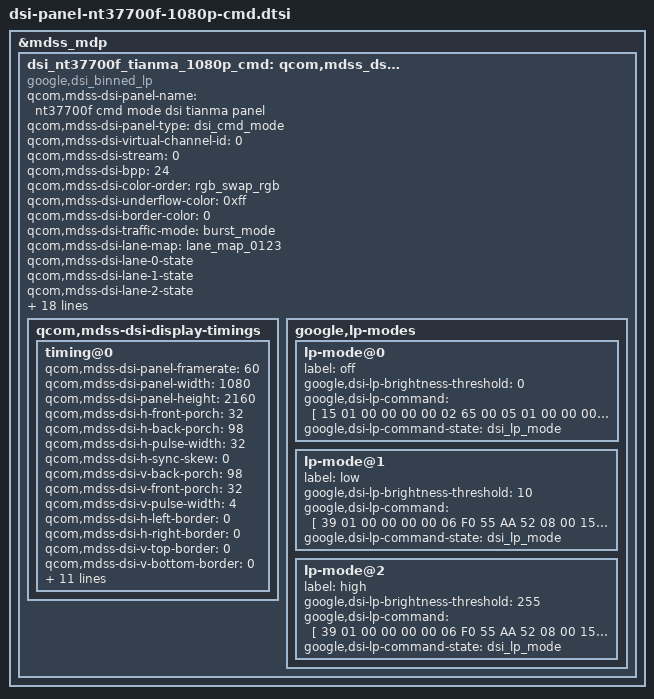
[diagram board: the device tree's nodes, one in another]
/* Copyright (c) 2018, The Linux Foundation. All rights reserved.
 *
 * This program is free software; you can redistribute it and/or modify
 * it under the terms of the GNU General Public License version 2 and
 * only version 2 as published by the Free Software Foundation.
 *
 * This program is distributed in the hope that it will be useful,
 * but WITHOUT ANY WARRANTY; without even the implied warranty of
 * MERCHANTABILITY or FITNESS FOR A PARTICULAR PURPOSE.  See the
 * GNU General Public License for more details.
 */

&mdss_mdp {
	dsi_nt37700f_tianma_1080p_cmd: qcom,mdss_dsi_nt37700f_tianma_1080p_cmd {
		compatible = "google,dsi_binned_lp";

		qcom,mdss-dsi-panel-name = "nt37700f cmd mode dsi tianma panel";
		qcom,mdss-dsi-panel-type = "dsi_cmd_mode";
		qcom,mdss-dsi-virtual-channel-id = <0>;
		qcom,mdss-dsi-stream = <0>;
		qcom,mdss-dsi-bpp = <24>;
		qcom,mdss-dsi-color-order = "rgb_swap_rgb";
		qcom,mdss-dsi-underflow-color = <0xff>;
		qcom,mdss-dsi-border-color = <0>;
		qcom,mdss-dsi-traffic-mode = "burst_mode";
		qcom,mdss-dsi-lane-map = "lane_map_0123";
		qcom,mdss-dsi-lane-0-state;
		qcom,mdss-dsi-lane-1-state;
		qcom,mdss-dsi-lane-2-state;
		qcom,mdss-dsi-lane-3-state;
		qcom,mdss-dsi-reset-sequence = <0 1>, <1 10>;
		qcom,mdss-dsi-dma-trigger = "trigger_sw";
		qcom,mdss-dsi-mdp-trigger = "none";
		qcom,mdss-dsi-te-pin-select = <1>;
		qcom,mdss-dsi-wr-mem-start = <0x2c>;
		qcom,mdss-dsi-wr-mem-continue = <0x3c>;
		qcom,mdss-dsi-te-dcs-command = <1>;
		qcom,mdss-dsi-te-check-enable;
		qcom,mdss-dsi-te-using-te-pin;
		qcom,mdss-dsi-lp11-init;
		qcom,mdss-dsi-tx-eot-append;

		qcom,mdss-pan-physical-width-dimension = <69>;
		qcom,mdss-pan-physical-height-dimension = <137>;

		qcom,mdss-dsi-bl-pmic-control-type = "bl_ctrl_dcs";
		qcom,mdss-dsi-bl-min-level = <9>;
		qcom,mdss-dsi-bl-max-level = <2047>; /* 11 bit */

		qcom,mdss-dsi-display-timings {
			timing@0 {
				qcom,mdss-dsi-panel-framerate = <60>;
				qcom,mdss-dsi-panel-width = <1080>;
				qcom,mdss-dsi-panel-height = <2160>;
				qcom,mdss-dsi-h-front-porch = <32>;
				qcom,mdss-dsi-h-back-porch = <98>;
				qcom,mdss-dsi-h-pulse-width = <32>;
				qcom,mdss-dsi-h-sync-skew = <0>;
				qcom,mdss-dsi-v-back-porch = <98>;
				qcom,mdss-dsi-v-front-porch = <32>;
				qcom,mdss-dsi-v-pulse-width = <4>;
				qcom,mdss-dsi-h-left-border = <0>;
				qcom,mdss-dsi-h-right-border = <0>;
				qcom,mdss-dsi-v-top-border = <0>;
				qcom,mdss-dsi-v-bottom-border = <0>;
				qcom,mdss-dsi-on-command = [
					39 01 00 00 00 00 06 F0 55 AA 52 08 00
					15 01 00 00 00 00 02 C0 56
					15 01 00 00 00 00 02 CA 52
					15 01 00 00 00 00 02 6F 06
					39 01 00 00 00 00 03 B5 2B 1A
					39 01 00 00 00 00 06 F0 55 AA 52 08 01
					39 01 00 00 00 00 03 CD 04 82
					39 01 00 00 00 00 06 F0 55 AA 52 08 02
					15 01 00 00 00 00 02 CC 00
					39 01 00 00 00 00 05 FF AA 55 A5 80
					15 01 00 00 00 00 02 6F 55
					15 01 00 00 00 00 02 F6 00
					15 01 00 00 00 00 02 6F 56
					15 01 00 00 00 00 02 F6 00
					39 01 00 00 00 00 05 FF AA 55 A5 81
					15 01 00 00 00 00 02 6F 07
					15 01 00 00 00 00 02 F3 07
					15 01 00 00 00 00 02 6F 05
					15 01 00 00 00 00 02 F3 25
					15 01 00 00 00 00 02 90 01
					39 01 00 00 00 00 05 2A 00 00 04 37
					39 01 00 00 00 00 05 2B 00 00 08 6F
					15 01 00 00 00 00 02 53 20
					15 01 00 00 00 00 02 35 00
					39 01 00 00 00 00 06 F0 55 AA 52 08 00
					15 01 00 00 00 00 02 C0 56
					39 01 00 00 00 00 06 F0 55 AA 52 08 02
					15 01 00 00 00 00 02 CD 00
					39 01 00 00 00 00 06 F0 55 AA 52 08 04
					39 01 00 00 00 00 03 D0 11 64
					15 01 00 00 00 00 02 6F 09
					15 01 00 00 00 00 04 B1 20 E6 08
					05 01 00 00 78 00 01 11
					05 01 00 00 00 00 01 29
				];
				qcom,mdss-dsi-off-command = [
					05 01 00 00 32 00 01 28
					05 01 00 00 64 00 01 10
				];
				qcom,mdss-dsi-lp1-command = [
					39 01 00 00 00 00 06 F0 55 AA 52 08 00
					15 01 00 00 00 00 02 6F 09
					15 01 00 00 00 00 02 B2 30
					/* emission 0x820: 50nit */
					39 01 00 00 00 00 1F B4
						83 33 33 33 33 33 33 33 33 38
						84 84 84 84 84 84 84 84 84 84
						84 84 84 84 84 84 84 84 84 20
					39 01 00 00 00 00 06 F0 55 AA 52 08 00
					15 01 00 00 00 00 02 6F 01
					39 01 00 00 00 00 04 C6 11 11 11
					15 01 00 00 00 00 02 6F 02
					15 01 00 00 00 00 02 C0 00
					39 01 00 00 00 00 06 F0 55 AA 52 08 01
					15 01 00 00 00 00 02 D2 10
					39 01 00 00 00 00 05 FF AA 55 A5 81
					15 01 00 00 00 00 02 6F 12
					15 01 00 00 00 00 02 F3 01
					05 01 00 00 00 00 01 39
					39 01 00 00 00 00 02 65 01
				];
				qcom,mdss-dsi-nolp-command = [
					15 01 00 00 00 00 02 65 00
					05 01 00 00 00 00 01 38
				];
				qcom,mdss-dsi-on-command-state = "dsi_lp_mode";
				qcom,mdss-dsi-off-command-state = "dsi_lp_mode";
				qcom,mdss-dsi-h-sync-pulse = <0>;
			};
		};

		google,lp-modes {
			lp-mode@0 {
				label = "off";
				google,dsi-lp-brightness-threshold = <0>;
				google,dsi-lp-command = [
					15 01 00 00 00 00 02 65 00
					05 01 00 00 00 00 01 38
				];
				google,dsi-lp-command-state = "dsi_lp_mode";
			};

			lp-mode@1 {
				label = "low";
				google,dsi-lp-brightness-threshold = <10>;
				google,dsi-lp-command = [
					39 01 00 00 00 00 06 F0 55 AA 52 08 00
					15 01 00 00 00 00 02 6F 09
					15 01 00 00 00 00 02 B2 30
					/* emission 0x871: 10nit */
					39 01 00 00 00 00 1F B4
						83 33 33 33 33 33 33 33 33 38
						84 84 84 84 84 84 84 84 84 84
						84 84 84 84 84 84 84 84 84 71
					39 01 00 00 00 00 06 F0 55 AA 52 08 00
					15 01 00 00 00 00 02 6F 01
					39 01 00 00 00 00 04 C6 11 11 11
					15 01 00 00 00 00 02 6F 02
					15 01 00 00 00 00 02 C0 00
					39 01 00 00 00 00 06 F0 55 AA 52 08 01
					15 01 00 00 00 00 02 D2 10
					39 01 00 00 00 00 05 FF AA 55 A5 81
					15 01 00 00 00 00 02 6F 12
					15 01 00 00 00 00 02 F3 01
					05 01 00 00 00 00 01 39
					39 01 00 00 00 00 02 65 01
				];
				google,dsi-lp-command-state = "dsi_lp_mode";
			};

			lp-mode@2 {
				label = "high";
				google,dsi-lp-brightness-threshold = <255>;
				google,dsi-lp-command = [
					39 01 00 00 00 00 06 F0 55 AA 52 08 00
					15 01 00 00 00 00 02 6F 09
					15 01 00 00 00 00 02 B2 30
					/* emission 0x820: 50nit */
					39 01 00 00 00 00 1F B4
						83 33 33 33 33 33 33 33 33 38
						84 84 84 84 84 84 84 84 84 84
						84 84 84 84 84 84 84 84 84 20
					39 01 00 00 00 00 06 F0 55 AA 52 08 00
					15 01 00 00 00 00 02 6F 01
					39 01 00 00 00 00 04 C6 11 11 11
					15 01 00 00 00 00 02 6F 02
					15 01 00 00 00 00 02 C0 00
					39 01 00 00 00 00 06 F0 55 AA 52 08 01
					15 01 00 00 00 00 02 D2 10
					39 01 00 00 00 00 05 FF AA 55 A5 81
					15 01 00 00 00 00 02 6F 12
					15 01 00 00 00 00 02 F3 01
					05 01 00 00 00 00 01 39
					39 01 00 00 00 00 02 65 01
				];
				google,dsi-lp-command-state = "dsi_lp_mode";
			};
		};
	};
};
